VERSION "HIPBNYYYYYYYYYYYYYYYYYYYYYYYYYYYYYYYYYYYYY/4/%%%/4/'%**4YYY///"

NS_ :

BS_:

BU_:

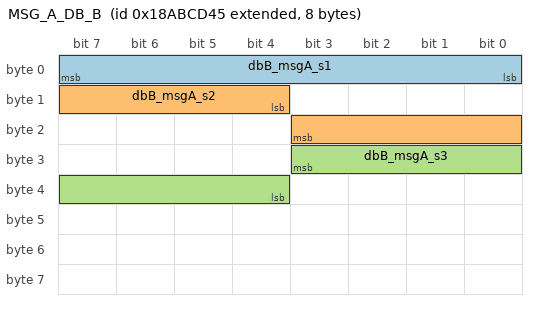
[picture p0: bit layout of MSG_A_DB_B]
BO_ 2561396037 MSG_A_DB_B: 8 Vector__XXX
 SG_ dbB_msgA_s1 : 7|8@0- (1,0) [0|0] "" Vector__XXX
 SG_ dbB_msgA_s2 : 12|8@1+ (1,0) [0|0] "" Vector__XXX
 SG_ dbB_msgA_s3 : 27|8@0+ (0.5,10.25) [0|0] "" Vector__XXX

BO_ 2566839392 MSG_B_DB_B: 8 Vector__XXX
 SG_ dbB_msgB_s1 : 2|16@1+ (1,0) [0|0] "" Vector__XXX

BO_ 2199008256 MSG_C_DB_B: 8 Vector__XXX
 SG_ NewSignal4_B : 0|8@1+ (1,0) [0|0] "" Vector__XXX

BO_ 2561395991 MSG_D_DB_B: 8 Vector__XXX
 SG_ dbB_msgD_s2 : 12|8@1+ (1,0) [0|0] "" Vector__XXX

CM_ BO_ 2561396037 "Same PGN";
CM_ SG_ 2561396037 dbB_msgA_s1 "format";
CM_ SG_ 2561396037 dbB_msgA_s2 "same";
CM_ SG_ 2561396037 dbB_msgA_s3 "scaling";
CM_ BO_ 2566839392 "Same Frame";
CM_ BO_ 2199008256 "Nothing";
